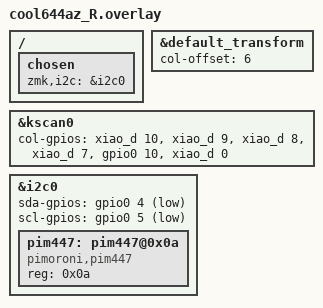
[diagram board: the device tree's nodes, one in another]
#include "cool644az.dtsi"

&default_transform {
    col-offset = <6>;
};

&kscan0 {
        col-gpios
            = <&xiao_d 10 GPIO_ACTIVE_HIGH>
            , <&xiao_d 9 GPIO_ACTIVE_HIGH> 
            , <&xiao_d 8 GPIO_ACTIVE_HIGH> 
            , <&xiao_d 7 GPIO_ACTIVE_HIGH> 
            , <&gpio0 10 GPIO_ACTIVE_HIGH>
            , <&xiao_d 0 GPIO_ACTIVE_HIGH> 
            ;
};


/ {
    chosen {
        zmk,i2c = &i2c0;
    };
};

&i2c0 {
    status = "okay";
    sda-gpios = <&gpio0 4 0(GPIO_ACTIVE_LOW | GPIO_PULL_UP)>;  // xiao ble gpio D4 
    scl-gpios = <&gpio0 5 0(GPIO_ACTIVE_LOW | GPIO_PULL_UP)>;  // xuao ble gpio D5
    pim447: pim447@0x0a {
        compatible = "pimoroni,pim447";
        reg = <0x0a>;
        status = "okay";
    };
};



